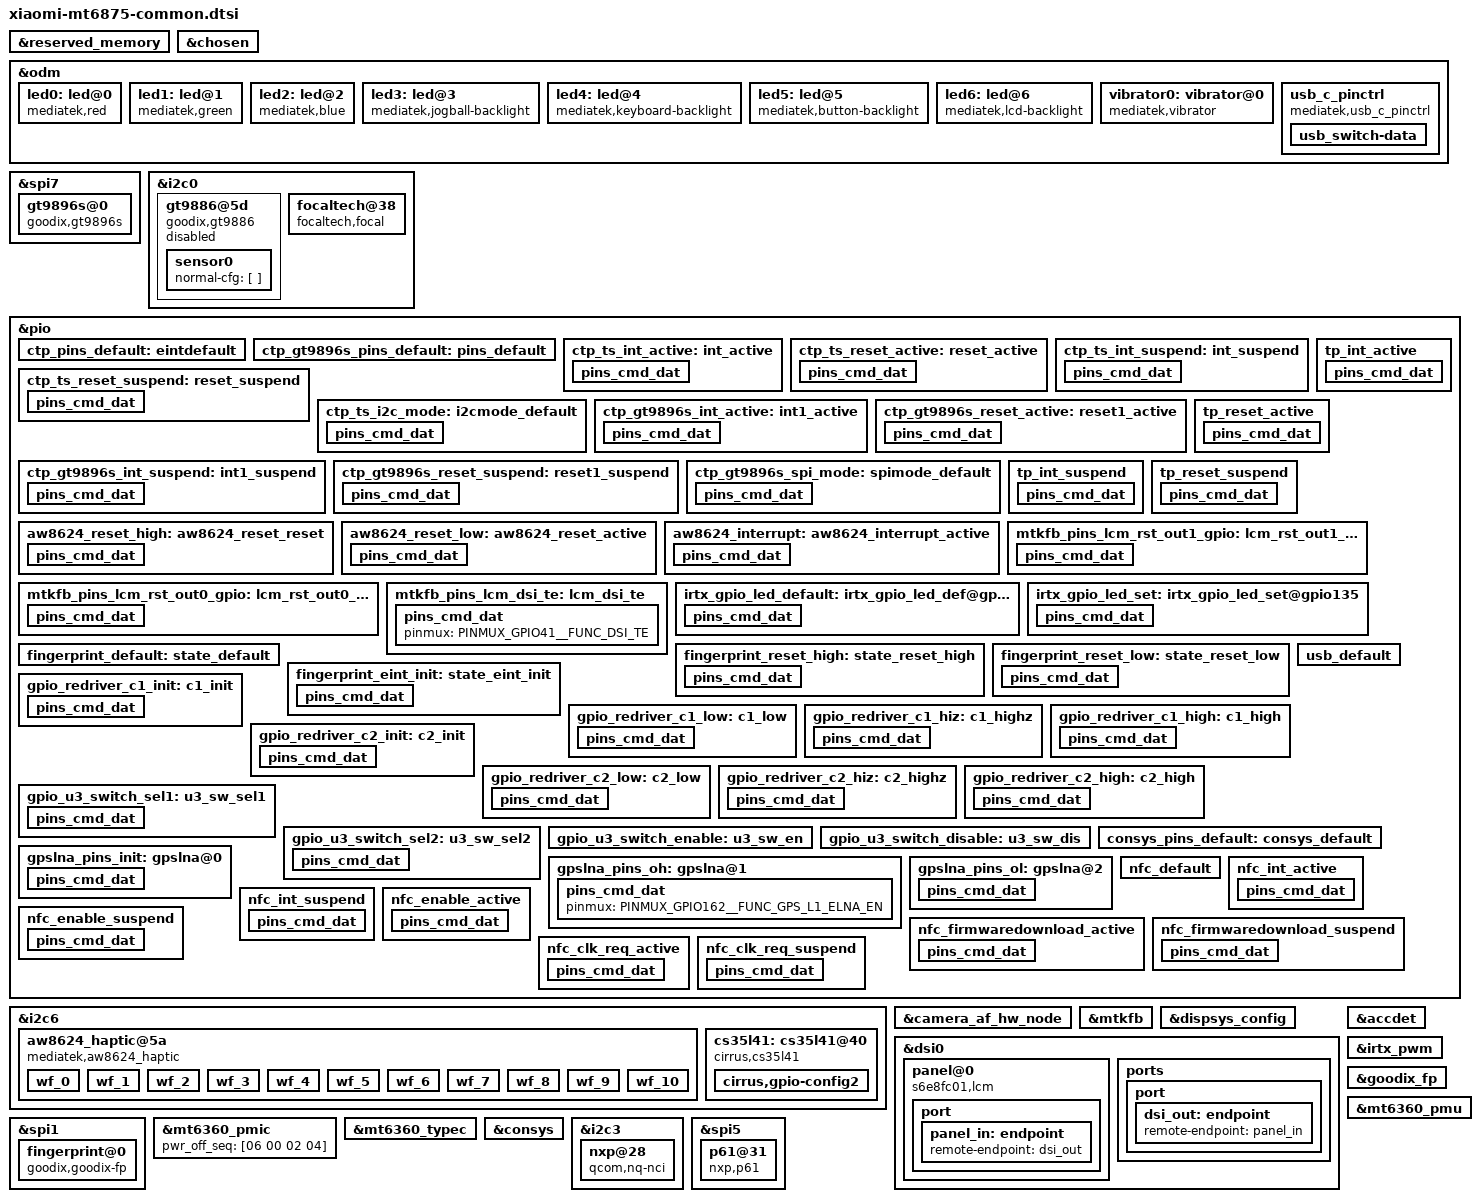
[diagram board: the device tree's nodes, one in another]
/*
 * Mediatek's mt6873 SoC device tree source
 *
 * Copyright (C) 2016 MediaTek Inc.
 * Copyright (C) 2020 XiaoMi, Inc.
 *
 * This program is free software; you can redistribute it and/or modify
 * it under the terms of the GNU General Public License version 2 as
 * published by the Free Software Foundation.
 *
 * This program is distributed in the hope that it will be useful,
 * but WITHOUT ANY WARRANTY; without even the implied warranty of
 * MERCHANTABILITY or FITNESS FOR A PARTICULAR PURPOSE.
 * See http://www.gnu.org/licenses/gpl-2.0.html for more details.
 */
/dts-v1/;
/plugin/;
#include <dt-bindings/interrupt-controller/irq.h>
#include <dt-bindings/interrupt-controller/arm-gic.h>
#include <dt-bindings/pinctrl/mt6873-pinfunc.h>

&reserved_memory {
};

/* chosen */
&chosen {

	atag,videolfb-fb_base_l = <0x7e605000>;
	atag,videolfb-fb_base_h = <0x0>;
	atag,videolfb-islcmfound = <1>;
	atag,videolfb-islcm_inited = <0>;
	atag,videolfb-fps= <6000>;
	atag,videolfb-vramSize= <0x1be0000>;
	atag,videolfb-lcmname=
		"nt35595_fhd_dsi_cmd_truly_nt50358_drv";
};

&odm {
	led0:led@0 {
		compatible = "mediatek,red";
		led_mode = <0>;
		data = <1>;
		pwm_config = <0 0 0 0 0>;
	};
	led1:led@1 {
		compatible = "mediatek,green";
		led_mode = <0>;
		data = <1>;
		pwm_config = <0 0 0 0 0>;
	};
	led2:led@2 {
		compatible = "mediatek,blue";
		led_mode = <0>;
		data = <1>;
		pwm_config = <0 0 0 0 0>;
	};
	led3:led@3 {
		compatible = "mediatek,jogball-backlight";
		led_mode = <0>;
		data = <1>;
		pwm_config = <0 0 0 0 0>;
	};
	led4:led@4 {
		compatible = "mediatek,keyboard-backlight";
		led_mode = <0>;
		data = <1>;
		pwm_config = <0 0 0 0 0>;
	};
	led5:led@5 {
		compatible = "mediatek,button-backlight";
		led_mode = <0>;
		data = <1>;
		pwm_config = <0 0 0 0 0>;
	};
	led6:led@6 {
		compatible = "mediatek,lcd-backlight";
		led_mode = <4>;
		data = <1>;
		pwm_config = <0 1 0 0 0>;
	};
	vibrator0:vibrator@0 {
		compatible = "mediatek,vibrator";
		vib_timer = <25>;
		vib_limit = <9>;
		vib_vol= <9>;
	};
	usb_c_pinctrl:usb_c_pinctrl {
		compatible = "mediatek,usb_c_pinctrl";
	};
};

/* TOUCH start */
&spi7 {
	status = "okay";
	#address-cells = <1>;
	#size-cells = <0>;
	pinctrl-names = "default", "gt9896s_int_active",
		"gt9896s_reset_active", "gt9896s_int_suspend",
		"gt9896s_reset_suspend", "gt9896s_spi_mode";
	pinctrl-0 = <&ctp_gt9896s_pins_default>;
	pinctrl-1 = <&ctp_gt9896s_int_active>;
	pinctrl-2 = <&ctp_gt9896s_reset_active>;
	pinctrl-3 = <&ctp_gt9896s_int_suspend>;
	pinctrl-4 = <&ctp_gt9896s_reset_suspend>;
	pinctrl-5 = <&ctp_gt9896s_spi_mode>;

	gt9896s@0 {
		compatible = "goodix,gt9896s";
		reg = <0>; //Same as CS ID
		spi-max-frequency = <1000000>;

		goodix,avdd-name = "vtouch";
		vtouch-supply = <&mt_pmic_vtp_ldo_reg>;
		goodix,reset-gpio = <&pio 20 0x0>;
		goodix,irq-gpio = <&pio 21 0x0>;
		goodix,irq-flags = <2>; /* 1:rising, 2:falling;*/
		goodix,panel-max-id = <10>;
		goodix,panel-max-x = <1080>;
		goodix,panel-max-y = <2280>;
		goodix,panel-max-w = <256>;
		goodix,panel-max-p = <256>;
		goodix,input-max-x = <1080>;
		goodix,input-max-y = <2280>;
		goodix,panel-key-map = <158 172 217>; /*BACK,HOMEPAGE,SEARCH*/
		goodix,power-on-delay-us = <10000>; /*10ms*/
		goodix,power-off-delay-us = <5000>;
		goodix,firmware-version = "6873v00";
		goodix,config-version = "6873v01";
		/*goodix,swap-axis;*/
		/*goodix,x2x;*/
		/*goodix,y2y;*/
		goodix,pen-enable;
		tpd-filter-enable = <0>;
		tpd-filter-pixel-density = <161>;
		tpd-filter-custom-prameters = <0 0 0 0 0 0 0 0 0 0 0 0>;
		tpd-filter-custom-speed = <0 0 0>;
	};
};

&i2c0 {
	clock-frequency = <400000>;
	pinctrl-names = "default", "ts_int_active",
		"ts_reset_active", "ts_int_suspend",
		"ts_reset_suspend", "ts_i2c_mode";
	pinctrl-0 = <&ctp_pins_default>;
	pinctrl-1 = <&ctp_ts_int_active>;
	pinctrl-2 = <&ctp_ts_reset_active>;
	pinctrl-3 = <&ctp_ts_int_suspend>;
	pinctrl-4 = <&ctp_ts_reset_suspend>;
	pinctrl-5 = <&ctp_ts_i2c_mode>;

	gt9886@5d {
		compatible = "goodix,gt9886";
		reg = <0x5d>;
		status = "disable";
		interrupt-parent = <&pio>;
		interrupts = <21 IRQ_TYPE_EDGE_FALLING 21 0>;
		vtouch-supply = <&mt_pmic_vtp_ldo_reg>;
		goodix,reset-gpio = <&pio 20 0x0>;
		goodix,irq-gpio = <&pio 21 0x0>;
		goodix,irq-flags = <2>; /* 1:rising, 2:falling;*/
		goodix,panel-max-id = <10>;
		goodix,panel-max-x = <1080>;
		goodix,panel-max-y = <2280>;
		goodix,panel-max-w = <256>;
		goodix,panel-max-p = <256>;
		goodix,input-max-x = <1080>;
		goodix,input-max-y = <2280>;
		goodix,panel-key-map = <158 172 217>; /*BACK,HOMEPAGE,SEARCH*/
		goodix,power-on-delay-us = <10000>; /*10ms*/
		goodix,power-off-delay-us = <5000>;
		goodix,firmware-version = "6885b1";
		goodix,config-version = "6885v9c";
		/*goodix,swap-axis;*/
		goodix,x2x;
		goodix,y2y;
		goodix,pen-enable;
		goodix,key-of-pen = <331 332>;/*BTN_STYLUS, BTN_STYLUS2*/
		tpd-filter-enable = <0>;
		tpd-filter-pixel-density = <161>;
		tpd-filter-custom-prameters = <0 0 0 0 0 0 0 0 0 0 0 0>;
		tpd-filter-custom-speed = <0 0 0>;
		sensor0 {
			normal-cfg = [
			];
		};
	};
};

&pio {
	ctp_pins_default: eintdefault {
	};
	ctp_gt9896s_pins_default: pins_default {
	};
	ctp_ts_int_active: int_active {
		pins_cmd_dat {
			pinmux = <PINMUX_GPIO21__FUNC_GPIO21>;
			slew-rate = <0>;
			bias-pull-up = <11>;
		};
	};
	ctp_ts_reset_active: reset_active {
		pins_cmd_dat {
			pinmux = <PINMUX_GPIO20__FUNC_GPIO20>;
			slew-rate = <1>;
			output-high;
		};
	};
	ctp_ts_int_suspend: int_suspend {
		pins_cmd_dat {
			pinmux = <PINMUX_GPIO21__FUNC_GPIO21>;
			slew-rate = <1>;
			output-low;
		};
	};
	ctp_ts_reset_suspend: reset_suspend {
		pins_cmd_dat {
			pinmux = <PINMUX_GPIO20__FUNC_GPIO20>;
			slew-rate = <1>;
			output-low;
		};
	};
	ctp_ts_i2c_mode: i2cmode_default {
		pins_cmd_dat {
			pinmux = <PINMUX_GPIO204__FUNC_SCL0>,
				<PINMUX_GPIO205__FUNC_SDA0>;
			mediatek,drive-strength-adv = <0>;/*EH[2:0]*/
		};
	};
	ctp_gt9896s_int_active: int1_active {
		pins_cmd_dat {
			pinmux = <PINMUX_GPIO21__FUNC_GPIO21>;
			slew-rate = <0>;
			bias-pull-up = <11>;
		};
	};
	ctp_gt9896s_reset_active: reset1_active {
		pins_cmd_dat {
			pinmux = <PINMUX_GPIO20__FUNC_GPIO20>;
			slew-rate = <1>;
			output-high;
		};
	};
	ctp_gt9896s_int_suspend: int1_suspend {
		pins_cmd_dat {
			pinmux = <PINMUX_GPIO21__FUNC_GPIO21>;
			slew-rate = <1>;
			output-low;
		};
	};
	ctp_gt9896s_reset_suspend: reset1_suspend {
		pins_cmd_dat {
			pinmux = <PINMUX_GPIO20__FUNC_GPIO20>;
			slew-rate = <1>;
			output-low;
		};
	};
	ctp_gt9896s_spi_mode: spimode_default {
		pins_cmd_dat {
			pinmux = <PINMUX_GPIO16__FUNC_SPI7_A_MI>,
				<PINMUX_GPIO17__FUNC_SPI7_A_MO>,
				<PINMUX_GPIO204__FUNC_SPI7_A_CLK>,
				<PINMUX_GPIO205__FUNC_SPI7_A_CSB>;
			drive-strength = <2>;
		};
	};
};

&i2c0 {
	focaltech@38 {
		compatible = "focaltech,focal";
		reg = <0x38>;
		status = "ok";
		interrupt-parent = <&pio>;
		interrupts = <21 IRQ_TYPE_EDGE_FALLING 21 0>;
		avdd-supply = <&mt_pmic_vtp_ldo_reg>;
		/*vddio-supply = <&mt_pmic_vcn33_1_wifi_ldo_reg>;*/
		/* avdd-supply = <&pm8150a_l1>; */
		/*focaltech,vdd-gpio = <&tlmm 8 0x0>;//3v*/
		focaltech,avdd-load = <200000>; //rated current 200mA
		focaltech,reset-gpio = <&pio 20 0x0>;
		focaltech,irq-gpio = <&pio 21 0x0>;
		focaltech,max-touch-number = <10>;
		focaltech,display-coords = <0 0 1080 2400>;
		focaltech,reset-when-resume;
		focaltech,lockdown-info-addr = <0x1E000>;
		focaltech,open-min = <2700>;
		pinctrl-names = "pmx_tp_active", "pmx_tp_suspend";
		pinctrl-0 = <&tp_int_active &tp_reset_active>;
		pinctrl-1 = <&tp_int_suspend &tp_reset_suspend>;
		/* focaltech,have-key; */
	};
};

&pio {
	tp_int_active: tp_int_active {
		pins_cmd_dat {
			pinmux = <PINMUX_GPIO21__FUNC_GPIO21>;
			slew-rate = <0>;
			bias-pull-up = <11>;
		};
	};

	tp_reset_active: tp_reset_active {
		pins_cmd_dat {
			pinmux = <PINMUX_GPIO20__FUNC_GPIO20>;
			slew-rate = <1>;
			drive-strength = <2>;
			bias-pull-up;
		};
	};

	tp_int_suspend: tp_int_suspend {
		pins_cmd_dat {
			pinmux = <PINMUX_GPIO21__FUNC_GPIO21>;
			slew-rate = <1>;
			input-enable;
		};
	};


	tp_reset_suspend: tp_reset_suspend {
		pins_cmd_dat {
			pinmux = <PINMUX_GPIO20__FUNC_GPIO20>;
			slew-rate = <1>;
			bias-disable;
		};
	};
};
/* TOUCH end */

/* aw8624 start */
&pio {
	aw8624_reset_high: aw8624_reset_reset {
		pins_cmd_dat {
			pinmux = <PINMUX_GPIO129__FUNC_GPIO129>;
			drive-strength = <2>;
			bias-disable;
			output-high;
		};
	};
	aw8624_reset_low: aw8624_reset_active {
		pins_cmd_dat {
			pinmux = <PINMUX_GPIO129__FUNC_GPIO129>;
			drive-strength = <2>;
			bias-disable;
			output-low;
		};
	};
	aw8624_interrupt: aw8624_interrupt_active {
		pins_cmd_dat {
			pinmux = <PINMUX_GPIO22__FUNC_GPIO22>;
			drive-strength = <2>;
			bias-pull-up;
			input-enable;
		};
	};
};

&i2c6 {
    status = "ok";
	aw8624_haptic@5a {
		compatible = "mediatek,aw8624_haptic";
		reg = <0x5a>;
		reset-gpio = <&pio 129 0x0>;
		irq-gpio = <&pio 22 0x0>;
		vib_mode = <0>; /* 0: RAM mode 1:CONT mode*/
		vib_f0_pre = < 2050 >;
		vib_f0_cali_percen = < 7 >;
		vib_cont_drv_lev = < 100 >;
		vib_cont_drv_lvl_ov = < 105 >;
		vib_cont_td = < 0xF06C >;
		vib_cont_zc_thr = < 0x08F8 >;
		vib_cont_num_brk = < 3 >;
		vib_f0_coeff = < 260 >; /*Don't modify it*/
		vib_f0_trace_parameter = < 9 3 1 31 >;
		vib_bemf_config = < 0x10 0x08 0x23 0xf8 >;
		vib_sw_brake = < 0x2c >;
		vib_tset = < 0x11 >;
		vib_func_parameter1 = < 1 >;
		vib_r_spare = < 0x68 >;
		vib_effect_id_boundary = < 10 >;
		vib_gain_flag = < 0 >;
		vib_effect_max = < 170 >;
		vib_trig_config = < 0 1 0 1 2
				0 1 0 1 2
				0 1 0 1 2 >;
		vib_bst_vol_default = < 0x1b >;
		vib_bst_vol_ram = < 0x1b >;
		vib_bst_vol_rtp = < 0x16 >;
		vib_rtp_time = < 20 20 20 20 20 20 20 20 20000 15000
				 15000 20000 25000 15000 30000 25000 20000 20000 20000 20000
				 20000 20000 20000 20000 20000 20000 20000 20000 20000 20000
				 20000 20000 20000 20000 20000 20000 20000 20000 20000 20000
				 20000 20000 20000 20000 20000 20000 20000 20000 20000 20000
				 20000 20000 20000 20000 20000 20000 20000 20000 20000 20000
				 20000 20000 20000 20000 20000 20000 20000 20000 20000 20000
				 20000 20000 20000 20000 20000 20000 20000 20000 20000 20000
				 20000 20000 20000 20000 20000 20000 20000 20000 20000 20000
				 20000 20000 20000 20000 20000 20000 20000 20000 20000 20000
				 20000 20000 20000 20000 20000 20000 20000 20000 20000 20000
				 20000 20000 20000 20000 20000 20000 20000 20000 20000 20000
				 20000 20000 20000 20000 20000 20000 20000 20000 20000 20000
				 20000 20000 20000 20000 20000 20000 20000 20000 20000 20000
				 20000 20000 20000 20000 20000 20000 20000 20000 20000 20000
				 20000 20000 20000 20000 20000 20000 20000 20000 20000 20000
				 20000 20000 20000 20000 20000 20000 20000 20000 20000 20000
				 20000 20000 20000 20000 20000 >;
		pinctrl-names = "aw8624_reset_reset","aw8624_reset_active","aw8624_interrupt_active";
		pinctrl-0 = <&aw8624_reset_low>;
		pinctrl-1 = <&aw8624_reset_high>;
		pinctrl-2 = <&aw8624_interrupt>;
		status = "ok";
		wf_0 {
			/*CLICK*/
			mtk,effect-id = <0>;
			mtk,wf-vmax-mv = <3600>;
			mtk,wf-pattern = [3e 3e];
			mtk,wf-brake-pattern = [02 01 00 00];
			mtk,wf-play-rate-us = <20000>;
		};
		wf_1 {
			/*DOUBLE CLICK*/
			mtk,effect-id = <1>;
			mtk,wf-vmax-mv = <3600>;
			mtk,wf-pattern = [7e 3e];
			mtk,wf-brake-pattern = [03 01 00 00];
			mtk,wf-play-rate-us = <20000>;
		};
		wf_2 {
			/*TICK*/
			mtk,effect-id = <2>;
			mtk,wf-vmax-mv = <3600>;
			mtk,wf-pattern = [7e 3e];
			mtk,wf-brake-pattern = [02 01 00 00];
			mtk,wf-play-rate-us = <13000>;
		};
		wf_3 {
			/*THUD*/
			mtk,effect-id = <3>;
			mtk,wf-vmax-mv = <3600>;
			mtk,wf-pattern = [3e 3e];
			mtk,wf-brake-pattern = [02 01 00 00];
			mtk,wf-play-rate-us = <10000>;
		};
		wf_4 {
			/*POP*/
			mtk,effect-id = <4>;
			mtk,wf-vmax-mv = <3600>;
			mtk,wf-pattern = [3e 3e];
			mtk,wf-brake-pattern = [02 01 00 00];
			mtk,wf-play-rate-us = <28000>;
		};
		wf_5 {
			/*HEAVY CLICK*/
			mtk,effect-id = <5>;
			mtk,wf-vmax-mv = <3600>;
			mtk,wf-pattern = [7e 7e 7e];
			mtk,wf-brake-pattern = [03 03 01 00];
			mtk,wf-play-rate-us = <10000>;
		};
		wf_6 {
			/*CLICK*/
			mtk,effect-id = <6>;
			mtk,wf-vmax-mv = <3600>;
			mtk,wf-pattern = [3e 3e];
			mtk,wf-brake-pattern = [02 01 00 00];
			mtk,wf-play-rate-us = <25000>;
		};
		wf_7 {
			/*DOUBLE CLICK*/
			mtk,effect-id = <7>;
			mtk,wf-vmax-mv = <3600>;
			mtk,wf-pattern = [7e 3e];
			mtk,wf-brake-pattern = [03 01 00 00];
			mtk,wf-play-rate-us = <25000>;
		};
		wf_8 {
			/*TICK*/
			mtk,effect-id = <8>;
			mtk,wf-vmax-mv = <3600>;
			mtk,wf-pattern = [7e 3e];
			mtk,wf-brake-pattern = [02 01 00 00];
			mtk,wf-play-rate-us = <35000>;
		};
		wf_9 {
			/*THUD*/
			mtk,effect-id = <9>;
			mtk,wf-vmax-mv = <3600>;
			mtk,wf-pattern = [3e 3e];
			mtk,wf-brake-pattern = [02 01 00 00];
			mtk,wf-play-rate-us = <15000>;
		};
		wf_10 {
			/*POP*/
			mtk,effect-id = <10>;
			mtk,wf-vmax-mv = <3600>;
			mtk,wf-pattern = [3e 3e];
			mtk,wf-brake-pattern = [02 01 00 00];
			mtk,wf-play-rate-us = <15000>;
		};
	};
};
/* aw8624 end */

/* DISPSYS GPIO standardization */

&pio {
	mtkfb_pins_lcm_rst_out1_gpio: lcm_rst_out1_gpio {
		pins_cmd_dat {
			pinmux = <PINMUX_GPIO42__FUNC_GPIO42>;
			slew-rate = <1>;
			output-high;
		};
	};

	mtkfb_pins_lcm_rst_out0_gpio: lcm_rst_out0_gpio {
		pins_cmd_dat {
			pinmux = <PINMUX_GPIO42__FUNC_GPIO42>;
			slew-rate = <1>;
			output-low;
		};
	};
	mtkfb_pins_lcm_dsi_te: lcm_dsi_te {
		pins_cmd_dat {
			pinmux = <PINMUX_GPIO41__FUNC_DSI_TE>;
		};
	};
};

&camera_af_hw_node {
	vcamaf-supply = <&fan53870_l7>;
	vcamois-supply = <&fan53870_l6>;
	status = "okay";
};

&mtkfb {
	pinctrl-names = "lcm_rst_out1_gpio", "lcm_rst_out0_gpio",
		"mode_te_te";

	pinctrl-0 = <&mtkfb_pins_lcm_rst_out1_gpio>;
	pinctrl-1 = <&mtkfb_pins_lcm_rst_out0_gpio>;
	pinctrl-2 = <&mtkfb_pins_lcm_dsi_te>;
	status = "okay";
};

&dispsys_config {
	pinctrl-names =
		"lcm_rst_out1_gpio", "lcm_rst_out0_gpio",
		"mode_te_te";
	pinctrl-0 = <&mtkfb_pins_lcm_rst_out1_gpio>;
	pinctrl-1 = <&mtkfb_pins_lcm_rst_out0_gpio>;
	pinctrl-2 = <&mtkfb_pins_lcm_dsi_te>;
	status = "okay";
};

&dsi0 {
	status = "okay";
	#address-cells = <1>;
	#size-cells = <0>;
	panel@0 {
		compatible = "s6e8fc01,lcm";
		reg = <0>;
		pm-enable-gpios = <&pio 29 0>;
		reset-gpios = <&pio 42 0>;
		pinctrl-names = "default";
		port {
			panel_in: endpoint {
				remote-endpoint = <&dsi_out>;
			};
		};
	};
	ports {
		port {
			dsi_out: endpoint {
				remote-endpoint = <&panel_in>;
			};
		};
	};
};

/* accdet start */
&accdet {
	/* accdet micbias voltage: 0x09:2.85v 0x08:2.8v 0x07,
	 * 2.7v;0x05,2.5v;0x02,1.9v
	 */
	accdet-mic-vol = <8>;
	/* accdet pwm_width, pwm_thresh, fall_delay, rise_delay
	 * debounce0, debounce1, debounce3, debounce4
	 * eint pwm_width, eint pwm_thresh
	 * eint deb(debounce0, debounce1, debounce2, debounce3), inv_debounce
	 */
	headset-mode-setting = <0x500 0x500 1 0x1f0
				0x800 0x1200 0x20 0x44
				0x4 0x1
				0x5 0x3 0x3 0x7 0xe>;
	accdet-plugout-debounce = <1>;
	/*1:ACC mode, 2:low cost without in bias, 6:low cost with in bias*/
	accdet-mic-mode = <2>;
	/*0--MD_MAX--UP_MAX--DW_MAX*/
	headset-three-key-threshold = <0 80 220 400>;
	headset-three-key-threshold-CDD = <0 121 192 600>;
	/*0--MD_MAX--VOICE_MAX--UP_MAX--DW_MAX*/
	headset-four-key-threshold = <0 58 121 192 400>;

	/* select VTH to 2v and 500k, use internal resitance */
	eint_use_ext_res = <0>;
	status = "okay";
};
/* accdet end */

/* IRTX GPIO Start */
&irtx_pwm {
	pwm_ch = <0>;
	pinctrl-names = "irtx_gpio_led_default", "irtx_gpio_led_set";
	pinctrl-0 = <&irtx_gpio_led_default>;
	pinctrl-1 = <&irtx_gpio_led_set>;
	status = "okay";
};
&pio {
	/* IRTX GPIO Settings -Start */
	/* default: GPIO0, output, high */
	irtx_gpio_led_default:irtx_gpio_led_def@gpio135 {
		pins_cmd_dat {
			pinmux = <PINMUX_GPIO135__FUNC_GPIO135>;
			slew-rate = <1>;
			bias-disable;
			output-low;
			input-schmitt-enable = <0>;
		};
	};

	irtx_gpio_led_set:irtx_gpio_led_set@gpio135 {
		pins_cmd_dat {
			pinmux = <PINMUX_GPIO135__FUNC_PWM_0>;
			slew-rate = <1>;
			output-high;
		};
	};
}; /* IRTX GPIO Settings -End */

/* FINGERPRINT start */
&spi1 {
	#address-cells = <1>;
	#size-cells = <0>;
	fingerprint@0 {
		compatible = "goodix,goodix-fp";
		reg = <0>;
		spi-max-frequency = <8000000>;
		netlink-event = <30>;
		vfp-supply = <&mt_pmic_vfp_ldo_reg>;
		power-type = <1>;
		status = "okay";
	};
};

&goodix_fp {
	pinctrl-names = "default", "reset_high", "reset_low", "eint_init";
	pinctrl-0 = <&fingerprint_default>;
	pinctrl-1 = <&fingerprint_reset_high>;
	pinctrl-2 = <&fingerprint_reset_low>;
	pinctrl-3 = <&fingerprint_eint_init>;
	interrupt-parent = <&pio>;
	interrupts = <15 IRQ_TYPE_EDGE_RISING 15 0>;
	status = "okay";
};

&pio {
	fingerprint_default: state_default {
	};
	fingerprint_reset_high: state_reset_high {
		pins_cmd_dat {
			pinmux = <PINMUX_GPIO14__FUNC_GPIO14>;
			slew-rate = <1>;
			output-high;
		};
	};
	fingerprint_reset_low: state_reset_low {
		pins_cmd_dat {
			pinmux = <PINMUX_GPIO14__FUNC_GPIO14>;
			slew-rate = <1>;
			output-low;
		};
	};
	fingerprint_eint_init: state_eint_init {
		pins_cmd_dat {
			pinmux = <PINMUX_GPIO15__FUNC_GPIO15>;
			slew-rate = <0>;
			bias-pull-up = <MTK_PUPD_SET_R1R0_10>;
			input-schmitt-enable;
		};
	};
};
/* FINGERPRINT end */

&mt6360_pmu {
	mt6360,intr_gpio_num = <24>; /* direct defined GPIO num */
	mt6360,intr_gpio = <&pio 24 0x0>;
};

&mt6360_pmic {
	pwr_off_seq = [06 00 02 04];
};

&mt6360_typec {
	mt6360pd,intr_gpio_num = <25>; /* direct defined GPIO num */
	mt6360pd,intr_gpio = <&pio 25 0x0>;
	mt6360pd,pcb_gpio = <&pio 19 0x0>;
	mt6360pd,pcb_gpio_num = <19>;
};

/* USB SWITCH GPIO start */
&pio {
	usb_default: usb_default {
	};

	gpio_redriver_c1_init: c1_init {
		pins_cmd_dat {
			pinmux = <PINMUX_GPIO113__FUNC_GPIO113>;
			slew-rate = <1>;
			output-low;
		};
	};

	gpio_redriver_c1_low: c1_low {
		pins_cmd_dat {
			pinmux = <PINMUX_GPIO113__FUNC_GPIO113>;
			slew-rate = <1>;
			output-low;
		};
	};

	gpio_redriver_c1_hiz: c1_highz {
		pins_cmd_dat {
			pinmux = <PINMUX_GPIO113__FUNC_GPIO113>;
			slew-rate= <0>;
			bias-disable;
		};
	};

	gpio_redriver_c1_high: c1_high {
		pins_cmd_dat {
			pinmux = <PINMUX_GPIO113__FUNC_GPIO113>;
			slew-rate = <1>;
			output-high;
		};
	};

	gpio_redriver_c2_init: c2_init {
		pins_cmd_dat {
			pinmux = <PINMUX_GPIO112__FUNC_GPIO112>;
			slew-rate = <1>;
			output-low;
		};
	};

	gpio_redriver_c2_low: c2_low {
		pins_cmd_dat {
			pinmux = <PINMUX_GPIO112__FUNC_GPIO112>;
			slew-rate = <1>;
			output-low;
		};
	};

	gpio_redriver_c2_hiz: c2_highz {
		pins_cmd_dat {
			pinmux = <PINMUX_GPIO112__FUNC_GPIO112>;
			slew-rate= <0>;
			bias-disable;
		};
	};

	gpio_redriver_c2_high: c2_high {
		pins_cmd_dat {
			pinmux = <PINMUX_GPIO112__FUNC_GPIO112>;
			slew-rate = <1>;
			output-high;
		};
	};

	gpio_u3_switch_sel1: u3_sw_sel1 {
		pins_cmd_dat {
			pinmux = <PINMUX_GPIO111__FUNC_GPIO111>;
			slew-rate = <1>;
			output-low;
		};
	};

	gpio_u3_switch_sel2: u3_sw_sel2 {
		pins_cmd_dat {
			pinmux = <PINMUX_GPIO111__FUNC_GPIO111>;
			slew-rate = <1>;
			output-high;
		};
	};

	gpio_u3_switch_enable: u3_sw_en {
	};

	gpio_u3_switch_disable: u3_sw_dis {
	};
};

&usb_c_pinctrl {
	pinctrl-names = "usb_default",
		"redrv_c1_init",
		"redrv_c1_low",
		"redrv_c1_hiz",
		"redrv_c1_high",
		"redrv_c2_init",
		"redrv_c2_low",
		"redrv_c2_hiz",
		"redrv_c2_high",
		"switch_sel1",
		"switch_sel2",
		"switch_enable",
		"switch_disable";

	pinctrl-0 = <&usb_default>;
	pinctrl-1 = <&gpio_redriver_c1_init>;
	pinctrl-2 = <&gpio_redriver_c1_low>;
	pinctrl-3 = <&gpio_redriver_c1_hiz>;
	pinctrl-4 = <&gpio_redriver_c1_high>;
	pinctrl-5 = <&gpio_redriver_c2_init>;
	pinctrl-6 = <&gpio_redriver_c2_low>;
	pinctrl-7 = <&gpio_redriver_c2_hiz>;
	pinctrl-8 = <&gpio_redriver_c2_high>;
	pinctrl-9 = <&gpio_u3_switch_sel1>;
	pinctrl-10 = <&gpio_u3_switch_sel2>;
	pinctrl-11 = <&gpio_u3_switch_enable>;
	pinctrl-12 = <&gpio_u3_switch_disable>;
	status = "okay";

	usb_switch-data {
		en_pin_num = <0>;
		en_pin_val = <0>;
		sel_pin_num = <111>;
		sel_pin_val = <1>;
		c1_pin_num = <113>;
		c1_pin_val = <2>;
		c2_pin_num = <112>;
		c2_pin_val = <1>;
	};
};
/* USB SWITCH GPIO end */

/* CONSYS GPIO standardization */
&pio {
	consys_pins_default: consys_default {
	};
	gpslna_pins_init: gpslna@0 {
		pins_cmd_dat {
			pinmux = <PINMUX_GPIO162__FUNC_GPIO162>;
			output-low;
		};
	};
	gpslna_pins_oh: gpslna@1 {
		pins_cmd_dat {
			pinmux = <PINMUX_GPIO162__FUNC_GPS_L1_ELNA_EN>;
		};
	};
	gpslna_pins_ol: gpslna@2 {
		pins_cmd_dat {
			pinmux = <PINMUX_GPIO162__FUNC_GPIO162>;
			output-low;
		};
	};
};
&consys {
	pinctrl-names = "default", "gps_lna_state_init",
		"gps_lna_state_oh", "gps_lna_state_ol";
	pinctrl-0 = <&consys_pins_default>;
	pinctrl-1 = <&gpslna_pins_init>;
	pinctrl-2 = <&gpslna_pins_oh>;
	pinctrl-3 = <&gpslna_pins_ol>;
	status = "okay";
};
/* CONSYS end */

&i2c3 {
	status = "okay";
	nxp@28 {
		compatible = "qcom,nq-nci";
		reg = <0x28>;
		qcom,nq-irq = <&pio 11 0x00>;
		interrupt-parent = <&pio>;
		interrupts = <11 IRQ_TYPE_LEVEL_HIGH 11 0>;
		qcom,nq-ven = <&pio 10 0x0>;
		qcom,nq-firm = <&pio 17 0x0>;
		qcom,nq-clkreq = <&pio 18 0x0>;
		//qcom,nq-esepwr = <&tlmm 42 0x00>;
		//interrupt-parent = <&tlmm>;
		//interrupts = <47 0>;
		interrupt-names = "nfc_irq";
		pinctrl-names = "default", "nfc_active", "nfc_suspend";
		pinctrl-0 = <&nfc_default>;
		pinctrl-1 = <&nfc_int_active &nfc_enable_active
				&nfc_clk_req_active &nfc_firmwaredownload_active>;
		pinctrl-2 = <&nfc_int_suspend &nfc_enable_suspend
                             &nfc_clk_req_suspend &nfc_firmwaredownload_suspend>;
	};

};
&pio {
	nfc_default: nfc_default {
	};
	nfc_int_active: nfc_int_active {
		pins_cmd_dat {
			pinmux = <PINMUX_GPIO11__FUNC_GPIO11>;
			slew-rate = <0>;
			drive-strength = <MTK_DRIVE_2mA>;
			bias-pull-up;
		};
	};

	nfc_int_suspend: nfc_int_suspend {
		pins_cmd_dat {
			pinmux = <PINMUX_GPIO11__FUNC_GPIO11>;
			slew-rate = <0>;
			drive-strength = <MTK_DRIVE_2mA>;
			bias-pull-up;
		};
	};

	nfc_enable_active: nfc_enable_active {
		pins_cmd_dat {
			pinmux = <PINMUX_GPIO10__FUNC_GPIO10>;
			slew-rate = <1>;
			output-high;
			drive-strength = <MTK_DRIVE_2mA>;
			bias-pull-up=<MTK_PUPD_SET_R1R0_11>;
		};
	};

	nfc_enable_suspend: nfc_enable_suspend {
		pins_cmd_dat {
			pinmux = <PINMUX_GPIO10__FUNC_GPIO10>;
			slew-rate = <1>;
			drive-strength = <MTK_DRIVE_2mA>;
			bias-disable;
		};
	};
	nfc_firmwaredownload_active: nfc_firmwaredownload_active {
		pins_cmd_dat {
			pinmux = <PINMUX_GPIO17__FUNC_GPIO17>;
			slew-rate = <1>;
			drive-strength = <MTK_DRIVE_2mA>;
			bias-pull-up;
		};
	};

	nfc_firmwaredownload_suspend: nfc_firmwaredownload_suspend {
		pins_cmd_dat {
			pinmux = <PINMUX_GPIO17__FUNC_GPIO17>;
			slew-rate = <1>;
			drive-strength = <MTK_DRIVE_2mA>;
			bias-disable;
		};
	};
	nfc_clk_req_active: nfc_clk_req_active {
		pins_cmd_dat {
			pinmux = <PINMUX_GPIO18__FUNC_SRCLKENAI0>;
			slew-rate = <0>;
			input-enable;
			drive-strength = <MTK_DRIVE_2mA>;
			bias-pull-up;
		};
	};

	nfc_clk_req_suspend: nfc_clk_req_suspend {
		pins_cmd_dat {
			pinmux = <PINMUX_GPIO18__FUNC_SRCLKENAI0>;
			slew-rate = <0>;
			input-enable;
			drive-strength = <MTK_DRIVE_2mA>;
			bias-pull-down;
		};
	};
};


&spi5 {
	#address-cells = <1>;
	#size-cells = <0>;
	p61@31 {
		compatible = "nxp,p61";
		reg = <0>;
		spi-max-frequency = <8000000>;
		status = "okay";
	};
};

/* Audio Start */
&i2c6 {
	status = "okay";
	cs35l41: cs35l41@40 {
		compatible = "cirrus,cs35l41";
		reg = <0x40>;
		reset-gpio = <&pio 30 0>;
		interrupt-parent = <&pio>;
		interrupts = <31 IRQ_TYPE_LEVEL_LOW 31 0>;
		irq-gpio = <&pio 31 0>;
		cirrus,boost-peak-milliamp = <4500>;
		cirrus,boost-ind-nanohenry = <1000>;
		cirrus,boost-cap-microfarad = <15>;
		cirrus,gpio-config2 {
			cirrus,gpio-src-select = <0x4>;
			cirrus,gpio-output-enable;
		};
	};
};
/* Audio End */

#include "cust_mt6873_camera.dtsi"
#include <k6875v1_64/cust.dtsi>
/*End of this file, DO NOT ADD ANYTHING HERE*/
